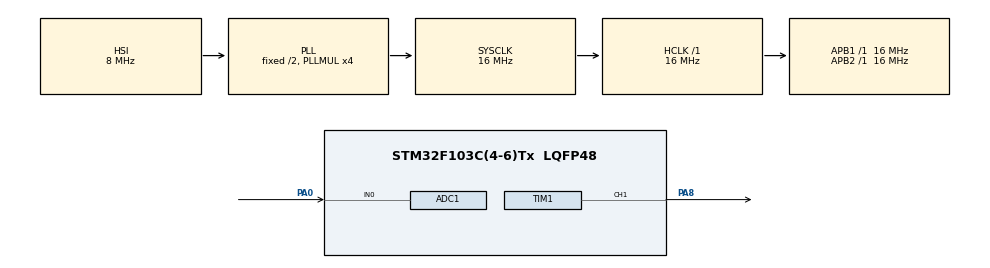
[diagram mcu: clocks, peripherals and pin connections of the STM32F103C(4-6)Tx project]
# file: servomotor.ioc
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ADC1.Channel-0\#ChannelRegularConversion=ADC_CHANNEL_0
ADC1.NbrOfConversionFlag=1
ADC1.Rank-0\#ChannelRegularConversion=1
ADC1.SamplingTime-0\#ChannelRegularConversion=ADC_SAMPLETIME_1CYCLE_5
ADC1.master=1
Mcu.Family=STM32F1
Mcu.Name=STM32F103C(4-6)Tx
Mcu.Package=LQFP48
NVIC.PriorityGroup=NVIC_PRIORITYGROUP_4
PA0-WKUP.Signal=ADCx_IN0
PA8.Signal=S_TIM1_CH1
PD0-OSC_IN.Mode=HSE-External-Oscillator
PD0-OSC_IN.Signal=RCC_OSC_IN
PD1-OSC_OUT.Mode=HSE-External-Oscillator
PD1-OSC_OUT.Signal=RCC_OSC_OUT
ProjectManager.HeapSize=0x200
ProjectManager.StackSize=0x400
ProjectManager.TargetToolchain=STM32CubeIDE
RCC.AHBFreq_Value=16000000
RCC.APB1Freq_Value=16000000
RCC.APB1TimFreq_Value=16000000
RCC.APB2Freq_Value=16000000
RCC.APB2TimFreq_Value=16000000
RCC.HCLKFreq_Value=16000000
RCC.PLLMUL=RCC_PLL_MUL4
RCC.SYSCLKFreq_VALUE=16000000
RCC.SYSCLKSource=RCC_SYSCLKSOURCE_PLLCLK
RCC.USBFreq_Value=16000000
SH.ADCx_IN0.0=ADC1_IN0,IN0
SH.S_TIM1_CH1.0=TIM1_CH1,PWM Generation1 CH1
TIM1.Channel-PWM\ Generation1\ CH1=TIM_CHANNEL_1
TIM1.Period=65535
VP_SYS_VS_ND.Mode=No_Debug
VP_TIM1_VS_ClockSourceINT.Mode=Internal
board=custom

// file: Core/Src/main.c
/* USER CODE BEGIN Header */
/**
  ******************************************************************************
  * @file           : main.c
  * @brief          : Main program body
  ******************************************************************************
  * @attention
  *
  * <h2><center>&copy; Copyright (c) 2026 STMicroelectronics.
  * All rights reserved.</center></h2>
  *
  * This software component is licensed by ST under BSD 3-Clause license,
  * the "License"; You may not use this file except in compliance with the
  * License. You may obtain a copy of the License at:
  *                        opensource.org/licenses/BSD-3-Clause
  *
  ******************************************************************************
  */
/* USER CODE END Header */

#include "main.h"

ADC_HandleTypeDef hadc1;

TIM_HandleTypeDef htim1;

void SystemClock_Config(void);
static void MX_GPIO_Init(void);
static void MX_ADC1_Init(void);
static void MX_TIM1_Init(void);
/* USER CODE BEGIN PFP */

static void set_servo(uint16_t );

/* USER CODE END PFP */

int main(void)
{
  /* USER CODE BEGIN 1 */

	uint16_t adc_val;

  /* USER CODE END 1 */

  /* MCU Configuration--------------------------------------------------------*/

  /* Reset of all peripherals, Initializes the Flash interface and the Systick. */
  HAL_Init();

  /* Configure the system clock */
  SystemClock_Config();

  /* Initialize all configured peripherals */
  MX_GPIO_Init();
  MX_ADC1_Init();
  MX_TIM1_Init();
  /* USER CODE BEGIN 2 */

  HAL_TIM_PWM_Start(&htim1, TIM_CHANNEL_1);

  TIM1->CR1 &= 0xFFFE;			// Turn OFF the timer
  TIM1->PSC = 16-1;				// 16Mhz/16 = 1 Prescalar
  TIM1->ARR = 20000-1;			// (20ms*1Mhz) - 1 = ARR;
  TIM1->CCR1 = 1000; 			// CCR = (Dutycycle * ARR);
  TIM1->CR1 |= 0x1;				// Turn ON the timer
//  TIM1->BDTR |= TIM_BDTR_MOE;

  /* USER CODE END 2 */

  /* Infinite loop */
  while (1)
  {

    /* USER CODE BEGIN 3 */

	  HAL_ADC_Start(&hadc1);
	  HAL_ADC_PollForConversion(&hadc1, 100);
	  adc_val = HAL_ADC_GetValue(&hadc1);
	  HAL_ADC_Stop(&hadc1);

	  set_servo(adc_val);
	  HAL_Delay(10);
  }
  /* USER CODE END 3 */
}

void SystemClock_Config(void)
{
  RCC_OscInitTypeDef RCC_OscInitStruct = {0};
  RCC_ClkInitTypeDef RCC_ClkInitStruct = {0};
  RCC_PeriphCLKInitTypeDef PeriphClkInit = {0};

  /** Initializes the CPU, AHB and APB busses clocks
  */
  RCC_OscInitStruct.OscillatorType = RCC_OSCILLATORTYPE_HSI;
  RCC_OscInitStruct.HSIState = RCC_HSI_ON;
  RCC_OscInitStruct.HSICalibrationValue = RCC_HSICALIBRATION_DEFAULT;
  RCC_OscInitStruct.PLL.PLLState = RCC_PLL_ON;
  RCC_OscInitStruct.PLL.PLLSource = RCC_PLLSOURCE_HSI_DIV2;
  RCC_OscInitStruct.PLL.PLLMUL = RCC_PLL_MUL4;
  if (HAL_RCC_OscConfig(&RCC_OscInitStruct) != HAL_OK)
  {
    Error_Handler();
  }
  /** Initializes the CPU, AHB and APB busses clocks
  */
  RCC_ClkInitStruct.ClockType = RCC_CLOCKTYPE_HCLK|RCC_CLOCKTYPE_SYSCLK
                              |RCC_CLOCKTYPE_PCLK1|RCC_CLOCKTYPE_PCLK2;
  RCC_ClkInitStruct.SYSCLKSource = RCC_SYSCLKSOURCE_PLLCLK;
  RCC_ClkInitStruct.AHBCLKDivider = RCC_SYSCLK_DIV1;
  RCC_ClkInitStruct.APB1CLKDivider = RCC_HCLK_DIV1;
  RCC_ClkInitStruct.APB2CLKDivider = RCC_HCLK_DIV1;

  if (HAL_RCC_ClockConfig(&RCC_ClkInitStruct, FLASH_LATENCY_0) != HAL_OK)
  {
    Error_Handler();
  }
  PeriphClkInit.PeriphClockSelection = RCC_PERIPHCLK_ADC;
  PeriphClkInit.AdcClockSelection = RCC_ADCPCLK2_DIV2;
  if (HAL_RCCEx_PeriphCLKConfig(&PeriphClkInit) != HAL_OK)
  {
    Error_Handler();
  }
}

static void MX_ADC1_Init(void)
{

  ADC_ChannelConfTypeDef sConfig = {0};

  /** Common config
  */
  hadc1.Instance = ADC1;
  hadc1.Init.ScanConvMode = ADC_SCAN_DISABLE;
  hadc1.Init.ContinuousConvMode = DISABLE;
  hadc1.Init.DiscontinuousConvMode = DISABLE;
  hadc1.Init.ExternalTrigConv = ADC_SOFTWARE_START;
  hadc1.Init.DataAlign = ADC_DATAALIGN_RIGHT;
  hadc1.Init.NbrOfConversion = 1;
  if (HAL_ADC_Init(&hadc1) != HAL_OK)
  {
    Error_Handler();
  }
  /** Configure Regular Channel
  */
  sConfig.Channel = ADC_CHANNEL_0;
  sConfig.Rank = ADC_REGULAR_RANK_1;
  sConfig.SamplingTime = ADC_SAMPLETIME_1CYCLE_5;
  if (HAL_ADC_ConfigChannel(&hadc1, &sConfig) != HAL_OK)
  {
    Error_Handler();
  }

}

static void MX_TIM1_Init(void)
{

  TIM_ClockConfigTypeDef sClockSourceConfig = {0};
  TIM_MasterConfigTypeDef sMasterConfig = {0};
  TIM_OC_InitTypeDef sConfigOC = {0};
  TIM_BreakDeadTimeConfigTypeDef sBreakDeadTimeConfig = {0};

  htim1.Instance = TIM1;
  htim1.Init.Prescaler = 8000;
  htim1.Init.CounterMode = TIM_COUNTERMODE_UP;
  htim1.Init.Period = 65535;
  htim1.Init.ClockDivision = TIM_CLOCKDIVISION_DIV1;
  htim1.Init.RepetitionCounter = 0;
  htim1.Init.AutoReloadPreload = TIM_AUTORELOAD_PRELOAD_DISABLE;
  if (HAL_TIM_Base_Init(&htim1) != HAL_OK)
  {
    Error_Handler();
  }
  sClockSourceConfig.ClockSource = TIM_CLOCKSOURCE_INTERNAL;
  if (HAL_TIM_ConfigClockSource(&htim1, &sClockSourceConfig) != HAL_OK)
  {
    Error_Handler();
  }
  if (HAL_TIM_PWM_Init(&htim1) != HAL_OK)
  {
    Error_Handler();
  }
  sMasterConfig.MasterOutputTrigger = TIM_TRGO_RESET;
  sMasterConfig.MasterSlaveMode = TIM_MASTERSLAVEMODE_DISABLE;
  if (HAL_TIMEx_MasterConfigSynchronization(&htim1, &sMasterConfig) != HAL_OK)
  {
    Error_Handler();
  }
  sConfigOC.OCMode = TIM_OCMODE_PWM1;
  sConfigOC.Pulse = 0;
  sConfigOC.OCPolarity = TIM_OCPOLARITY_HIGH;
  sConfigOC.OCNPolarity = TIM_OCNPOLARITY_HIGH;
  sConfigOC.OCFastMode = TIM_OCFAST_DISABLE;
  sConfigOC.OCIdleState = TIM_OCIDLESTATE_RESET;
  sConfigOC.OCNIdleState = TIM_OCNIDLESTATE_RESET;
  if (HAL_TIM_PWM_ConfigChannel(&htim1, &sConfigOC, TIM_CHANNEL_1) != HAL_OK)
  {
    Error_Handler();
  }
  sBreakDeadTimeConfig.OffStateRunMode = TIM_OSSR_DISABLE;
  sBreakDeadTimeConfig.OffStateIDLEMode = TIM_OSSI_DISABLE;
  sBreakDeadTimeConfig.LockLevel = TIM_LOCKLEVEL_OFF;
  sBreakDeadTimeConfig.DeadTime = 0;
  sBreakDeadTimeConfig.BreakState = TIM_BREAK_DISABLE;
  sBreakDeadTimeConfig.BreakPolarity = TIM_BREAKPOLARITY_HIGH;
  sBreakDeadTimeConfig.AutomaticOutput = TIM_AUTOMATICOUTPUT_DISABLE;
  if (HAL_TIMEx_ConfigBreakDeadTime(&htim1, &sBreakDeadTimeConfig) != HAL_OK)
  {
    Error_Handler();
  }
  HAL_TIM_MspPostInit(&htim1);

}

static void MX_GPIO_Init(void)
{

  /* GPIO Ports Clock Enable */
  __HAL_RCC_GPIOD_CLK_ENABLE();
  __HAL_RCC_GPIOA_CLK_ENABLE();

}

/* USER CODE BEGIN 4 */

static void set_servo(uint16_t val1)
{
//    uint16_t pulse;
    uint32_t dummy_var;

	dummy_var = (4395.6*val1)/100000;
	dummy_var = (5555.56*dummy_var)/1000;
	dummy_var = 19000-dummy_var;

	TIM1->CR1 &= 0xFFFE;
	TIM1->CCR1 = dummy_var;
	TIM1->CR1 |= 0x1;
}

/* USER CODE END 4 */

void Error_Handler(void)
{
}

/************************ (C) COPYRIGHT STMicroelectronics *****END OF FILE****/
